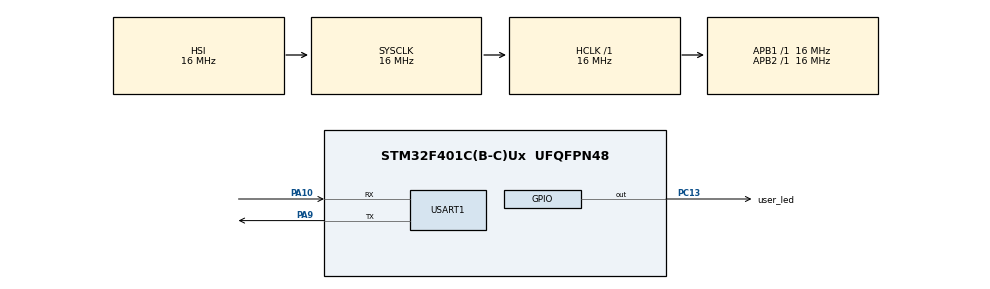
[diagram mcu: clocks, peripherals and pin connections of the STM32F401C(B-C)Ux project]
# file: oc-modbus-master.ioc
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FREERTOS.Tasks01=defaultTask,0,128,StartDefaultTask,Default,NULL,Dynamic,NULL,NULL
Mcu.Family=STM32F4
Mcu.Name=STM32F401C(B-C)Ux
Mcu.Package=UFQFPN48
NVIC.PriorityGroup=NVIC_PRIORITYGROUP_4
NVIC.TIM1_UP_TIM10_IRQn=true\:15\:0\:false\:false\:true\:false\:false\:true\:true
NVIC.TimeBase=TIM1_UP_TIM10_IRQn
NVIC.TimeBaseIP=TIM1
PA10.Mode=Asynchronous
PA10.Signal=USART1_RX
PA13.Mode=Serial_Wire
PA13.Signal=SYS_JTMS-SWDIO
PA14.Mode=Serial_Wire
PA14.Signal=SYS_JTCK-SWCLK
PA9.Mode=Asynchronous
PA9.Signal=USART1_TX
PC13-ANTI_TAMP.GPIO_Label=user_led
PC13-ANTI_TAMP.Signal=GPIO_Output
PH0\ -\ OSC_IN.Mode=HSE-External-Oscillator
PH0\ -\ OSC_IN.Signal=RCC_OSC_IN
PH1\ -\ OSC_OUT.Mode=HSE-External-Oscillator
PH1\ -\ OSC_OUT.Signal=RCC_OSC_OUT
ProjectManager.HeapSize=0x200
ProjectManager.StackSize=0x400
ProjectManager.TargetToolchain=STM32CubeIDE
RCC.AHBFreq_Value=16000000
RCC.APB1Freq_Value=16000000
RCC.APB2Freq_Value=16000000
RCC.CortexFreq_Value=16000000
RCC.HSE_VALUE=25000000
RCC.HSI_VALUE=16000000
RCC.SYSCLKFreq_VALUE=16000000
RCC.VCOOutputFreq_Value=192000000
USART1.VirtualMode=VM_ASYNC
VP_FREERTOS_VS_CMSIS_V1.Mode=CMSIS_V1
VP_SYS_VS_tim1.Mode=TIM1
board=custom

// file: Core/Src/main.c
/* USER CODE BEGIN Header */
/**
  ******************************************************************************
  * @file           : main.c
  * @brief          : Main program body
  ******************************************************************************
  * @attention
  *
  * Copyright (c) 2025 STMicroelectronics.
  * All rights reserved.
  *
  * This software is licensed under terms that can be found in the LICENSE file
  * in the root directory of this software component.
  * If no LICENSE file comes with this software, it is provided AS-IS.
  *
  ******************************************************************************
  */
/* USER CODE END Header */
#include "main.h"
#include "cmsis_os.h"

/* USER CODE BEGIN Includes */
#include "custom_types.h"
#include "string.h"
#include "stdio.h"

/* USER CODE END Includes */

UART_HandleTypeDef huart1;

osThreadId defaultTaskHandle;

osThreadId x_task_get_device_diagnostics_handle;
osThreadId x_task_print_to_terminal_handle;

/* USER CODE BEGIN PV */

// diagnostics variable
diagnostics_type_t diagnostics;

char uart_tx_buffer[255]; // todo: remove magic buffer size

/* USER CODE END PV */

void SystemClock_Config(void);
static void MX_GPIO_Init(void);
static void MX_USART1_UART_Init(void);
void StartDefaultTask(void const * argument);

/* USER CODE BEGIN PFP */

/**
 * Function prototypes
 */
void UART_print(const char* message);

/**
 * Task prototypes
 *
 */
void x_task_get_device_diagnostics(void const* argument);
void x_task_print_to_terminal(void const* argument);

/* USER CODE END PFP */

/* USER CODE BEGIN 0 */

/**
 * @fn void UART_print(const char*)
 * @brief This function prints messages to serial terminal
 *
 * @param message char buffer to print
 */
void UART_print(const char* message) {
	HAL_UART_Transmit(&huart1,(uint8_t*)message , strlen(message), HAL_MAX_DELAY);
}

/* USER CODE END 0 */

int main(void)
{

  /* MCU Configuration--------------------------------------------------------*/

  /* Reset of all peripherals, Initializes the Flash interface and the Systick. */
  HAL_Init();

  /* Configure the system clock */
  SystemClock_Config();

  /* Initialize all configured peripherals */
  MX_GPIO_Init();
  MX_USART1_UART_Init();
  /* USER CODE BEGIN 2 */

  HAL_UART_Transmit(&huart1, (uint8_t*)"=======MODBUS SLAVE======= \r\n\n", strlen("=======MODBUS SLAVE======= \r\n\n"), HAL_MAX_DELAY);
  HAL_Delay(1000);

  /* USER CODE END 2 */

  /* Create the thread(s) */
  /* definition and creation of defaultTask */
  osThreadDef(defaultTask, StartDefaultTask, osPriorityNormal, 0, 128);
  defaultTaskHandle = osThreadCreate(osThread(defaultTask), NULL);

  /* USER CODE BEGIN RTOS_THREADS */
  /* add threads, ... */

  osThreadDef(get_device_diagnostics, x_task_get_device_diagnostics, osPriorityIdle + 3, 0, 128); // task to get the device parameters
  x_task_get_device_diagnostics_handle = osThreadCreate(osThread(get_device_diagnostics), NULL);

  osThreadDef(print_to_terminal, x_task_print_to_terminal, osPriorityNormal, 0, 128); // task to print to UART if using UART debug
  x_task_print_to_terminal_handle = osThreadCreate(osThread(print_to_terminal), NULL);

  // todo -> check successful task creation

  /* USER CODE END RTOS_THREADS */

  /* Start scheduler */
  osKernelStart();

  /* We should never get here as control is now taken by the scheduler */

  /* Infinite loop */
  while (1)
  {

  }
}

void SystemClock_Config(void)
{
  RCC_OscInitTypeDef RCC_OscInitStruct = {0};
  RCC_ClkInitTypeDef RCC_ClkInitStruct = {0};

  /** Configure the main internal regulator output voltage
  */
  __HAL_RCC_PWR_CLK_ENABLE();
  __HAL_PWR_VOLTAGESCALING_CONFIG(PWR_REGULATOR_VOLTAGE_SCALE2);

  /** Initializes the RCC Oscillators according to the specified parameters
  * in the RCC_OscInitTypeDef structure.
  */
  RCC_OscInitStruct.OscillatorType = RCC_OSCILLATORTYPE_HSI;
  RCC_OscInitStruct.HSIState = RCC_HSI_ON;
  RCC_OscInitStruct.HSICalibrationValue = RCC_HSICALIBRATION_DEFAULT;
  RCC_OscInitStruct.PLL.PLLState = RCC_PLL_NONE;
  if (HAL_RCC_OscConfig(&RCC_OscInitStruct) != HAL_OK)
  {
    Error_Handler();
  }

  /** Initializes the CPU, AHB and APB buses clocks
  */
  RCC_ClkInitStruct.ClockType = RCC_CLOCKTYPE_HCLK|RCC_CLOCKTYPE_SYSCLK
                              |RCC_CLOCKTYPE_PCLK1|RCC_CLOCKTYPE_PCLK2;
  RCC_ClkInitStruct.SYSCLKSource = RCC_SYSCLKSOURCE_HSI;
  RCC_ClkInitStruct.AHBCLKDivider = RCC_SYSCLK_DIV1;
  RCC_ClkInitStruct.APB1CLKDivider = RCC_HCLK_DIV1;
  RCC_ClkInitStruct.APB2CLKDivider = RCC_HCLK_DIV1;

  if (HAL_RCC_ClockConfig(&RCC_ClkInitStruct, FLASH_LATENCY_0) != HAL_OK)
  {
    Error_Handler();
  }
}

static void MX_USART1_UART_Init(void)
{

  huart1.Instance = USART1;
  huart1.Init.BaudRate = 115200;
  huart1.Init.WordLength = UART_WORDLENGTH_8B;
  huart1.Init.StopBits = UART_STOPBITS_1;
  huart1.Init.Parity = UART_PARITY_NONE;
  huart1.Init.Mode = UART_MODE_TX_RX;
  huart1.Init.HwFlowCtl = UART_HWCONTROL_NONE;
  huart1.Init.OverSampling = UART_OVERSAMPLING_16;
  if (HAL_UART_Init(&huart1) != HAL_OK)
  {
    Error_Handler();
  }

}

static void MX_GPIO_Init(void)
{
  GPIO_InitTypeDef GPIO_InitStruct = {0};

  /* GPIO Ports Clock Enable */
  __HAL_RCC_GPIOC_CLK_ENABLE();
  __HAL_RCC_GPIOH_CLK_ENABLE();
  __HAL_RCC_GPIOA_CLK_ENABLE();

  /*Configure GPIO pin Output Level */
  HAL_GPIO_WritePin(user_led_GPIO_Port, user_led_Pin, GPIO_PIN_RESET);

  /*Configure GPIO pin : user_led_Pin */
  GPIO_InitStruct.Pin = user_led_Pin;
  GPIO_InitStruct.Mode = GPIO_MODE_OUTPUT_PP;
  GPIO_InitStruct.Pull = GPIO_NOPULL;
  GPIO_InitStruct.Speed = GPIO_SPEED_FREQ_LOW;
  HAL_GPIO_Init(user_led_GPIO_Port, &GPIO_InitStruct);

}

/* USER CODE BEGIN 4 */

/**
 * @fn void x_task_get_device_diagnostics(const void*)
 * @brief Get the device diagnostics values (see firmware docs for more info)
 *
 * @param args parameter to the task
 */
void x_task_get_device_diagnostics(void const* args) {

	for(;;) {
		diagnostics.chip_parameters.uid[0] = HAL_GetUIDw0();		// read the chip's UID
		diagnostics.chip_parameters.uid[0] = HAL_GetUIDw0();
		diagnostics.chip_parameters.uid[2] = HAL_GetUIDw0();        // todo: create a 96 bit struct for this (64 bit + 32 bit)

		uint32_t core_freq = HAL_RCC_GetHCLKFreq();					// read the HCLK frequency. todo: read PCLK low freq speed
		diagnostics.chip_parameters.core_frequency = core_freq;

		diagnostics.free_heap_size = xPortGetFreeHeapSize();			// free heap size at the time this function is called
		diagnostics.minimum_ever_free_heap_size = xPortGetMinimumEverFreeHeapSize();

		sprintf(uart_tx_buffer,   // package uart message
				"UID: %lu%lu%lu, HCLK: %lu, FREE_HEAP: %u, MIN_EVER_HEAP: %u \r\n",
				diagnostics.chip_parameters.uid[0],
				diagnostics.chip_parameters.uid[1],
				diagnostics.chip_parameters.uid[2],
				diagnostics.chip_parameters.core_frequency,
				diagnostics.free_heap_size,
				diagnostics.minimum_ever_free_heap_size
		);

		vTaskDelay(pdMS_TO_TICKS(10));

	}
}

/**
 * @fn void x_task_print_to_terminal(const void*)
 * @brief This task prints data to terminal
 *
 * @param arguments
 */
void x_task_print_to_terminal(void const* arguments ) {

	for(;;) {
		// todo: use event group to queue peek here
		// use mutex to prevent writing to the uart tx buffer while the buffer is printing
		UART_print(uart_tx_buffer);
		vTaskDelay(pdMS_TO_TICKS(5)); 	// prevent task starvation
	}
}

/* USER CODE END 4 */

void StartDefaultTask(void const * argument)
{
  for(;;)
  {
    osDelay(1);
  }
}

void HAL_TIM_PeriodElapsedCallback(TIM_HandleTypeDef *htim)
{
  if (htim->Instance == TIM1)
  {
    HAL_IncTick();
  }
}

void Error_Handler(void)
{
  __disable_irq();
  while (1)
  {
  }
}
